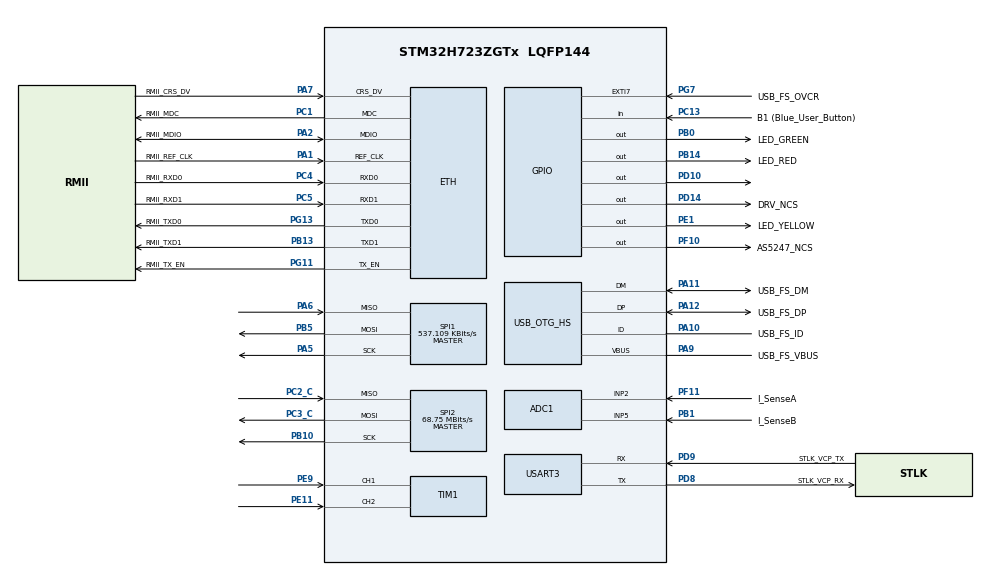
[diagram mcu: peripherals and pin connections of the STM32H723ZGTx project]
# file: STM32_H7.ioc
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ADC1.Channel-3\#ChannelRegularConversion=ADC_CHANNEL_2
ADC1.NbrOfConversionFlag=1
ADC1.OffsetNumber-3\#ChannelRegularConversion=ADC_OFFSET_NONE
ADC1.OffsetSignedSaturation-3\#ChannelRegularConversion=DISABLE
ADC1.Rank-3\#ChannelRegularConversion=1
ADC1.SamplingTime-3\#ChannelRegularConversion=ADC_SAMPLETIME_1CYCLE_5
ADC1.master=1
ETH.MediaInterface=HAL_ETH_RMII_MODE
Mcu.Family=STM32H7
Mcu.Name=STM32H723ZGTx
Mcu.Package=LQFP144
NVIC.PriorityGroup=NVIC_PRIORITYGROUP_4
PA1.GPIO_Label=RMII_REF_CLK
PA1.Mode=RMII
PA1.Signal=ETH_REF_CLK
PA10.GPIO_Label=USB_FS_ID
PA10.Mode=OTG/Dual-Role-Device-FS
PA10.Signal=USB_OTG_HS_ID
PA11.GPIO_Label=USB_FS_DM
PA11.Mode=OTG/Dual-Role-Device-FS
PA11.Signal=USB_OTG_HS_DM
PA12.GPIO_Label=USB_FS_DP
PA12.Mode=OTG/Dual-Role-Device-FS
PA12.Signal=USB_OTG_HS_DP
PA13(JTMS/SWDIO).GPIO_Label=SWDIO
PA13(JTMS/SWDIO).Mode=Trace_Asynchronous_SW
PA13(JTMS/SWDIO).Signal=DEBUG_JTMS-SWDIO
PA14(JTCK/SWCLK).GPIO_Label=SWCLK
PA14(JTCK/SWCLK).Mode=Trace_Asynchronous_SW
PA14(JTCK/SWCLK).Signal=DEBUG_JTCK-SWCLK
PA2.GPIO_Label=RMII_MDIO
PA2.Mode=RMII
PA2.Signal=ETH_MDIO
PA5.Mode=Full_Duplex_Master
PA5.Signal=SPI1_SCK
PA6.Mode=Full_Duplex_Master
PA6.Signal=SPI1_MISO
PA7.GPIO_Label=RMII_CRS_DV
PA7.Mode=RMII
PA7.Signal=ETH_CRS_DV
PA9.GPIO_Label=USB_FS_VBUS
PA9.Mode=Activate_VBUS_FS
PA9.Signal=USB_OTG_HS_VBUS
PB0.GPIO_Label=LED_GREEN
PB0.Signal=GPIO_Output
PB1.GPIO_Label=I_SenseB
PB1.Signal=ADCx_INP5
PB10.Mode=Full_Duplex_Master
PB10.Signal=SPI2_SCK
PB13.GPIO_Label=RMII_TXD1
PB13.Mode=RMII
PB13.Signal=ETH_TXD1
PB14.GPIO_Label=LED_RED
PB14.Signal=GPIO_Output
PB3(JTDO/TRACESWO).GPIO_Label=SWO
PB3(JTDO/TRACESWO).Mode=Trace_Asynchronous_SW
PB3(JTDO/TRACESWO).Signal=DEBUG_JTDO-SWO
PB5.Mode=Full_Duplex_Master
PB5.Signal=SPI1_MOSI
PC1.GPIO_Label=RMII_MDC
PC1.Mode=RMII
PC1.Signal=ETH_MDC
PC13.GPIO_Label=B1 (Blue_User_Button)
PC13.Signal=GPIO_Input
PC14-OSC32_IN.Mode=LSE-External-Oscillator
PC14-OSC32_IN.Signal=RCC_OSC32_IN
PC15-OSC32_OUT.Mode=LSE-External-Oscillator
PC15-OSC32_OUT.Signal=RCC_OSC32_OUT
PC2_C.Mode=Full_Duplex_Master
PC2_C.Signal=SPI2_MISO
PC3_C.Mode=Full_Duplex_Master
PC3_C.Signal=SPI2_MOSI
PC4.GPIO_Label=RMII_RXD0
PC4.Mode=RMII
PC4.Signal=ETH_RXD0
PC5.GPIO_Label=RMII_RXD1
PC5.Mode=RMII
PC5.Signal=ETH_RXD1
PD10.Signal=GPIO_Output
PD14.GPIO_Label=DRV_NCS
PD14.Signal=GPIO_Output
PD8.GPIO_Label=STLK_VCP_RX
PD8.Mode=Asynchronous
PD8.Signal=USART3_TX
PD9.GPIO_Label=STLK_VCP_TX
PD9.Mode=Asynchronous
PD9.Signal=USART3_RX
PE1.GPIO_Label=LED_YELLOW
PE1.Signal=GPIO_Output
PE11.Signal=S_TIM1_CH2
PE9.Signal=S_TIM1_CH1
PF10.GPIO_Label=AS5247_NCS
PF10.Signal=GPIO_Output
PF11.GPIO_Label=I_SenseA
PF11.Mode=IN2-Single-Ended
PF11.Signal=ADC1_INP2
PG11.GPIO_Label=RMII_TX_EN
PG11.Mode=RMII
PG11.Signal=ETH_TX_EN
PG13.GPIO_Label=RMII_TXD0
PG13.Mode=RMII
PG13.Signal=ETH_TXD0
PG7.GPIO_Label=USB_FS_OVCR
PG7.Signal=GPXTI7
PH0-OSC_IN.GPIO_Label=MCO
PH0-OSC_IN.Mode=HSE-External-Clock-Source
PH0-OSC_IN.Signal=RCC_OSC_IN
PH1-OSC_OUT.Signal=RCC_OSC_OUT
ProjectManager.HeapSize=0x200
ProjectManager.StackSize=0x400
ProjectManager.TargetToolchain=STM32CubeIDE
RCC.ADCFreq_Value=96000000
RCC.APB1Freq_Value=137500000
RCC.APB2Freq_Value=137500000
RCC.APB3Freq_Value=137500000
RCC.APB4Freq_Value=137500000
RCC.CortexFreq_Value=550000000
RCC.D1PPRE=RCC_APB3_DIV2
RCC.D2PPRE1=RCC_APB1_DIV2
RCC.D2PPRE2=RCC_APB2_DIV2
RCC.D3PPRE=RCC_APB4_DIV2
RCC.DIVM1=4
RCC.DIVM2=1
RCC.DIVN1=275
RCC.DIVN2=24
RCC.DIVP1=1
RCC.DIVQ1=4
RCC.HCLKFreq_Value=275000000
RCC.HPRE=RCC_HCLK_DIV2
RCC.HSE_VALUE=8000000
RCC.PLLFRACN=0
RCC.PLLSourceVirtual=RCC_PLLSOURCE_HSE
RCC.SYSCLKFreq_VALUE=550000000
RCC.SYSCLKSource=RCC_SYSCLKSOURCE_PLLCLK
RCC.USBCLockSelection=RCC_USBCLKSOURCE_HSI48
RCC.USBFreq_Value=48000000
SH.ADCx_INP5.0=ADC1_INP5,IN5-Single-Ended
SH.S_TIM1_CH1.0=TIM1_CH1,Encoder_Interface
SH.S_TIM1_CH2.0=TIM1_CH2,Encoder_Interface
SPI1.BaudRatePrescaler=SPI_BAUDRATEPRESCALER_256
SPI1.CLKPhase=SPI_PHASE_2EDGE
SPI1.CalculateBaudRate=537.109 KBits/s
SPI1.DataSize=SPI_DATASIZE_16BIT
SPI1.Direction=SPI_DIRECTION_2LINES
SPI1.Mode=SPI_MODE_MASTER
SPI1.NSSPMode=SPI_NSS_PULSE_ENABLE
SPI1.VirtualType=VM_MASTER
SPI2.CalculateBaudRate=68.75 MBits/s
SPI2.Direction=SPI_DIRECTION_2LINES
SPI2.Mode=SPI_MODE_MASTER
SPI2.VirtualType=VM_MASTER
USART3.VirtualMode-Asynchronous=VM_ASYNC
board=NUCLEO-H723ZG

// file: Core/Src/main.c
/* USER CODE BEGIN Header */
/**
  ******************************************************************************
  * @file           : main.c
  * @brief          : Main program body
  ******************************************************************************
  * @attention
  *
  * <h2><center>&copy; Copyright (c) 2021 STMicroelectronics.
  * All rights reserved.</center></h2>
  *
  * This software component is licensed by ST under BSD 3-Clause license,
  * the "License"; You may not use this file except in compliance with the
  * License. You may obtain a copy of the License at:
  *                        opensource.org/licenses/BSD-3-Clause
  *
  ******************************************************************************
  */
/* USER CODE END Header */
#include "main.h"
#include "string.h"

/* USER CODE BEGIN Includes */
#include "as5247u.h"
/* USER CODE END Includes */

#if defined ( __ICCARM__ ) /*!< IAR Compiler */

#pragma location=0x30040000
ETH_DMADescTypeDef  DMARxDscrTab[ETH_RX_DESC_CNT]; /* Ethernet Rx DMA Descriptors */
#pragma location=0x30040060
ETH_DMADescTypeDef  DMATxDscrTab[ETH_TX_DESC_CNT]; /* Ethernet Tx DMA Descriptors */
#pragma location=0x30040200
uint8_t Rx_Buff[ETH_RX_DESC_CNT][ETH_MAX_PACKET_SIZE]; /* Ethernet Receive Buffers */

#elif defined ( __CC_ARM )  /* MDK ARM Compiler */

__attribute__((at(0x30040000))) ETH_DMADescTypeDef  DMARxDscrTab[ETH_RX_DESC_CNT]; /* Ethernet Rx DMA Descriptors */
__attribute__((at(0x30040060))) ETH_DMADescTypeDef  DMATxDscrTab[ETH_TX_DESC_CNT]; /* Ethernet Tx DMA Descriptors */
__attribute__((at(0x30040200))) uint8_t Rx_Buff[ETH_RX_DESC_CNT][ETH_MAX_PACKET_SIZE]; /* Ethernet Receive Buffer */

#elif defined ( __GNUC__ ) /* GNU Compiler */

ETH_DMADescTypeDef DMARxDscrTab[ETH_RX_DESC_CNT] __attribute__((section(".RxDecripSection"))); /* Ethernet Rx DMA Descriptors */
ETH_DMADescTypeDef DMATxDscrTab[ETH_TX_DESC_CNT] __attribute__((section(".TxDecripSection")));   /* Ethernet Tx DMA Descriptors */
uint8_t Rx_Buff[ETH_RX_DESC_CNT][ETH_MAX_PACKET_SIZE] __attribute__((section(".RxArraySection"))); /* Ethernet Receive Buffers */

#endif

ETH_TxPacketConfig TxConfig;
ADC_HandleTypeDef hadc1;

ETH_HandleTypeDef heth;

SPI_HandleTypeDef hspi1;
SPI_HandleTypeDef hspi2;

TIM_HandleTypeDef htim1;

UART_HandleTypeDef huart3;

void SystemClock_Config(void);
static void MX_GPIO_Init(void);
static void MX_ETH_Init(void);
static void MX_USART3_UART_Init(void);
static void MX_USB_OTG_HS_USB_Init(void);
static void MX_SPI1_Init(void);
static void MX_ADC1_Init(void);
static void MX_TIM1_Init(void);
static void MX_SPI2_Init(void);

int main(void)
{

  /* MCU Configuration--------------------------------------------------------*/

  /* Reset of all peripherals, Initializes the Flash interface and the Systick. */
  HAL_Init();

  /* Configure the system clock */
  SystemClock_Config();

  /* Initialize all configured peripherals */
  MX_GPIO_Init();
  MX_ETH_Init();
  MX_USART3_UART_Init();
  MX_USB_OTG_HS_USB_Init();
  MX_SPI1_Init();
  MX_ADC1_Init();
  MX_TIM1_Init();
  MX_SPI2_Init();
  /* USER CODE BEGIN 2 */
  AS5247U enc;
  AS5247U_Initialize(&enc, &hspi1, NULL,AS5247_NCS_GPIO_Port, 0, AS5247_NCS_Pin);
  /* USER CODE END 2 */

  /* Infinite loop */
  /* USER CODE BEGIN WHILE */
  while (1)
  {
//      HAL_GPIO_WritePin(AS5247_NCS_GPIO_Port, AS5247_NCS_Pin, GPIO_PIN_SET);
//      HAL_Delay(100);
	  uint16_t data = AS5247U_GetErrorReg(&enc);
      HAL_Delay(100);

    /* USER CODE END WHILE */

  }
}

void SystemClock_Config(void)
{
  RCC_OscInitTypeDef RCC_OscInitStruct = {0};
  RCC_ClkInitTypeDef RCC_ClkInitStruct = {0};

  /** Supply configuration update enable
  */
  HAL_PWREx_ConfigSupply(PWR_LDO_SUPPLY);
  /** Configure the main internal regulator output voltage
  */
  __HAL_PWR_VOLTAGESCALING_CONFIG(PWR_REGULATOR_VOLTAGE_SCALE0);

  while(!__HAL_PWR_GET_FLAG(PWR_FLAG_VOSRDY)) {}
  /** Macro to configure the PLL clock source
  */
  __HAL_RCC_PLL_PLLSOURCE_CONFIG(RCC_PLLSOURCE_HSE);
  /** Initializes the RCC Oscillators according to the specified parameters
  * in the RCC_OscInitTypeDef structure.
  */
  RCC_OscInitStruct.OscillatorType = RCC_OSCILLATORTYPE_HSI48|RCC_OSCILLATORTYPE_HSE;
  RCC_OscInitStruct.HSEState = RCC_HSE_BYPASS;
  RCC_OscInitStruct.HSI48State = RCC_HSI48_ON;
  RCC_OscInitStruct.PLL.PLLState = RCC_PLL_ON;
  RCC_OscInitStruct.PLL.PLLSource = RCC_PLLSOURCE_HSE;
  RCC_OscInitStruct.PLL.PLLM = 4;
  RCC_OscInitStruct.PLL.PLLN = 275;
  RCC_OscInitStruct.PLL.PLLP = 1;
  RCC_OscInitStruct.PLL.PLLQ = 4;
  RCC_OscInitStruct.PLL.PLLR = 2;
  RCC_OscInitStruct.PLL.PLLRGE = RCC_PLL1VCIRANGE_1;
  RCC_OscInitStruct.PLL.PLLVCOSEL = RCC_PLL1VCOWIDE;
  RCC_OscInitStruct.PLL.PLLFRACN = 0;
  if (HAL_RCC_OscConfig(&RCC_OscInitStruct) != HAL_OK)
  {
    Error_Handler();
  }
  /** Initializes the CPU, AHB and APB buses clocks
  */
  RCC_ClkInitStruct.ClockType = RCC_CLOCKTYPE_HCLK|RCC_CLOCKTYPE_SYSCLK
                              |RCC_CLOCKTYPE_PCLK1|RCC_CLOCKTYPE_PCLK2
                              |RCC_CLOCKTYPE_D3PCLK1|RCC_CLOCKTYPE_D1PCLK1;
  RCC_ClkInitStruct.SYSCLKSource = RCC_SYSCLKSOURCE_PLLCLK;
  RCC_ClkInitStruct.SYSCLKDivider = RCC_SYSCLK_DIV1;
  RCC_ClkInitStruct.AHBCLKDivider = RCC_HCLK_DIV2;
  RCC_ClkInitStruct.APB3CLKDivider = RCC_APB3_DIV2;
  RCC_ClkInitStruct.APB1CLKDivider = RCC_APB1_DIV2;
  RCC_ClkInitStruct.APB2CLKDivider = RCC_APB2_DIV2;
  RCC_ClkInitStruct.APB4CLKDivider = RCC_APB4_DIV2;

  if (HAL_RCC_ClockConfig(&RCC_ClkInitStruct, FLASH_LATENCY_3) != HAL_OK)
  {
    Error_Handler();
  }
}

static void MX_ADC1_Init(void)
{

  ADC_MultiModeTypeDef multimode = {0};
  ADC_ChannelConfTypeDef sConfig = {0};

  /** Common config
  */
  hadc1.Instance = ADC1;
  hadc1.Init.ClockPrescaler = ADC_CLOCK_ASYNC_DIV1;
  hadc1.Init.Resolution = ADC_RESOLUTION_16B;
  hadc1.Init.ScanConvMode = ADC_SCAN_DISABLE;
  hadc1.Init.EOCSelection = ADC_EOC_SINGLE_CONV;
  hadc1.Init.LowPowerAutoWait = DISABLE;
  hadc1.Init.ContinuousConvMode = DISABLE;
  hadc1.Init.NbrOfConversion = 1;
  hadc1.Init.DiscontinuousConvMode = DISABLE;
  hadc1.Init.ExternalTrigConv = ADC_SOFTWARE_START;
  hadc1.Init.ExternalTrigConvEdge = ADC_EXTERNALTRIGCONVEDGE_NONE;
  hadc1.Init.ConversionDataManagement = ADC_CONVERSIONDATA_DR;
  hadc1.Init.Overrun = ADC_OVR_DATA_PRESERVED;
  hadc1.Init.LeftBitShift = ADC_LEFTBITSHIFT_NONE;
  hadc1.Init.OversamplingMode = DISABLE;
  if (HAL_ADC_Init(&hadc1) != HAL_OK)
  {
    Error_Handler();
  }
  /** Configure the ADC multi-mode
  */
  multimode.Mode = ADC_MODE_INDEPENDENT;
  if (HAL_ADCEx_MultiModeConfigChannel(&hadc1, &multimode) != HAL_OK)
  {
    Error_Handler();
  }
  /** Configure Regular Channel
  */
  sConfig.Channel = ADC_CHANNEL_2;
  sConfig.Rank = ADC_REGULAR_RANK_1;
  sConfig.SamplingTime = ADC_SAMPLETIME_1CYCLE_5;
  sConfig.SingleDiff = ADC_SINGLE_ENDED;
  sConfig.OffsetNumber = ADC_OFFSET_NONE;
  sConfig.Offset = 0;
  sConfig.OffsetSignedSaturation = DISABLE;
  if (HAL_ADC_ConfigChannel(&hadc1, &sConfig) != HAL_OK)
  {
    Error_Handler();
  }

}

static void MX_ETH_Init(void)
{

   static uint8_t MACAddr[6];

  heth.Instance = ETH;
  MACAddr[0] = 0x00;
  MACAddr[1] = 0x80;
  MACAddr[2] = 0xE1;
  MACAddr[3] = 0x00;
  MACAddr[4] = 0x00;
  MACAddr[5] = 0x00;
  heth.Init.MACAddr = &MACAddr[0];
  heth.Init.MediaInterface = HAL_ETH_RMII_MODE;
  heth.Init.TxDesc = DMATxDscrTab;
  heth.Init.RxDesc = DMARxDscrTab;
  heth.Init.RxBuffLen = 1524;

  if (HAL_ETH_Init(&heth) != HAL_OK)
  {
    Error_Handler();
  }

  memset(&TxConfig, 0 , sizeof(ETH_TxPacketConfig));
  TxConfig.Attributes = ETH_TX_PACKETS_FEATURES_CSUM | ETH_TX_PACKETS_FEATURES_CRCPAD;
  TxConfig.ChecksumCtrl = ETH_CHECKSUM_IPHDR_PAYLOAD_INSERT_PHDR_CALC;
  TxConfig.CRCPadCtrl = ETH_CRC_PAD_INSERT;

}

static void MX_SPI1_Init(void)
{

  /* SPI1 parameter configuration*/
  hspi1.Instance = SPI1;
  hspi1.Init.Mode = SPI_MODE_MASTER;
  hspi1.Init.Direction = SPI_DIRECTION_2LINES;
  hspi1.Init.DataSize = SPI_DATASIZE_16BIT;
  hspi1.Init.CLKPolarity = SPI_POLARITY_LOW;
  hspi1.Init.CLKPhase = SPI_PHASE_2EDGE;
  hspi1.Init.NSS = SPI_NSS_SOFT;
  hspi1.Init.BaudRatePrescaler = SPI_BAUDRATEPRESCALER_256;
  hspi1.Init.FirstBit = SPI_FIRSTBIT_MSB;
  hspi1.Init.TIMode = SPI_TIMODE_DISABLE;
  hspi1.Init.CRCCalculation = SPI_CRCCALCULATION_DISABLE;
  hspi1.Init.CRCPolynomial = 0x0;
  hspi1.Init.NSSPMode = SPI_NSS_PULSE_ENABLE;
  hspi1.Init.NSSPolarity = SPI_NSS_POLARITY_LOW;
  hspi1.Init.FifoThreshold = SPI_FIFO_THRESHOLD_01DATA;
  hspi1.Init.TxCRCInitializationPattern = SPI_CRC_INITIALIZATION_ALL_ZERO_PATTERN;
  hspi1.Init.RxCRCInitializationPattern = SPI_CRC_INITIALIZATION_ALL_ZERO_PATTERN;
  hspi1.Init.MasterSSIdleness = SPI_MASTER_SS_IDLENESS_00CYCLE;
  hspi1.Init.MasterInterDataIdleness = SPI_MASTER_INTERDATA_IDLENESS_00CYCLE;
  hspi1.Init.MasterReceiverAutoSusp = SPI_MASTER_RX_AUTOSUSP_DISABLE;
  hspi1.Init.MasterKeepIOState = SPI_MASTER_KEEP_IO_STATE_DISABLE;
  hspi1.Init.IOSwap = SPI_IO_SWAP_DISABLE;
  if (HAL_SPI_Init(&hspi1) != HAL_OK)
  {
    Error_Handler();
  }

}

static void MX_SPI2_Init(void)
{

  /* SPI2 parameter configuration*/
  hspi2.Instance = SPI2;
  hspi2.Init.Mode = SPI_MODE_MASTER;
  hspi2.Init.Direction = SPI_DIRECTION_2LINES;
  hspi2.Init.DataSize = SPI_DATASIZE_4BIT;
  hspi2.Init.CLKPolarity = SPI_POLARITY_LOW;
  hspi2.Init.CLKPhase = SPI_PHASE_1EDGE;
  hspi2.Init.NSS = SPI_NSS_SOFT;
  hspi2.Init.BaudRatePrescaler = SPI_BAUDRATEPRESCALER_2;
  hspi2.Init.FirstBit = SPI_FIRSTBIT_MSB;
  hspi2.Init.TIMode = SPI_TIMODE_DISABLE;
  hspi2.Init.CRCCalculation = SPI_CRCCALCULATION_DISABLE;
  hspi2.Init.CRCPolynomial = 0x0;
  hspi2.Init.NSSPMode = SPI_NSS_PULSE_ENABLE;
  hspi2.Init.NSSPolarity = SPI_NSS_POLARITY_LOW;
  hspi2.Init.FifoThreshold = SPI_FIFO_THRESHOLD_01DATA;
  hspi2.Init.TxCRCInitializationPattern = SPI_CRC_INITIALIZATION_ALL_ZERO_PATTERN;
  hspi2.Init.RxCRCInitializationPattern = SPI_CRC_INITIALIZATION_ALL_ZERO_PATTERN;
  hspi2.Init.MasterSSIdleness = SPI_MASTER_SS_IDLENESS_00CYCLE;
  hspi2.Init.MasterInterDataIdleness = SPI_MASTER_INTERDATA_IDLENESS_00CYCLE;
  hspi2.Init.MasterReceiverAutoSusp = SPI_MASTER_RX_AUTOSUSP_DISABLE;
  hspi2.Init.MasterKeepIOState = SPI_MASTER_KEEP_IO_STATE_DISABLE;
  hspi2.Init.IOSwap = SPI_IO_SWAP_DISABLE;
  if (HAL_SPI_Init(&hspi2) != HAL_OK)
  {
    Error_Handler();
  }

}

static void MX_TIM1_Init(void)
{

  TIM_Encoder_InitTypeDef sConfig = {0};
  TIM_MasterConfigTypeDef sMasterConfig = {0};

  htim1.Instance = TIM1;
  htim1.Init.Prescaler = 0;
  htim1.Init.CounterMode = TIM_COUNTERMODE_UP;
  htim1.Init.Period = 65535;
  htim1.Init.ClockDivision = TIM_CLOCKDIVISION_DIV1;
  htim1.Init.RepetitionCounter = 0;
  htim1.Init.AutoReloadPreload = TIM_AUTORELOAD_PRELOAD_DISABLE;
  sConfig.EncoderMode = TIM_ENCODERMODE_TI1;
  sConfig.IC1Polarity = TIM_ICPOLARITY_RISING;
  sConfig.IC1Selection = TIM_ICSELECTION_DIRECTTI;
  sConfig.IC1Prescaler = TIM_ICPSC_DIV1;
  sConfig.IC1Filter = 0;
  sConfig.IC2Polarity = TIM_ICPOLARITY_RISING;
  sConfig.IC2Selection = TIM_ICSELECTION_DIRECTTI;
  sConfig.IC2Prescaler = TIM_ICPSC_DIV1;
  sConfig.IC2Filter = 0;
  if (HAL_TIM_Encoder_Init(&htim1, &sConfig) != HAL_OK)
  {
    Error_Handler();
  }
  sMasterConfig.MasterOutputTrigger = TIM_TRGO_RESET;
  sMasterConfig.MasterOutputTrigger2 = TIM_TRGO2_RESET;
  sMasterConfig.MasterSlaveMode = TIM_MASTERSLAVEMODE_DISABLE;
  if (HAL_TIMEx_MasterConfigSynchronization(&htim1, &sMasterConfig) != HAL_OK)
  {
    Error_Handler();
  }

}

static void MX_USART3_UART_Init(void)
{

  huart3.Instance = USART3;
  huart3.Init.BaudRate = 115200;
  huart3.Init.WordLength = UART_WORDLENGTH_8B;
  huart3.Init.StopBits = UART_STOPBITS_1;
  huart3.Init.Parity = UART_PARITY_NONE;
  huart3.Init.Mode = UART_MODE_TX_RX;
  huart3.Init.HwFlowCtl = UART_HWCONTROL_NONE;
  huart3.Init.OverSampling = UART_OVERSAMPLING_16;
  huart3.Init.OneBitSampling = UART_ONE_BIT_SAMPLE_DISABLE;
  huart3.Init.ClockPrescaler = UART_PRESCALER_DIV1;
  huart3.AdvancedInit.AdvFeatureInit = UART_ADVFEATURE_NO_INIT;
  if (HAL_UART_Init(&huart3) != HAL_OK)
  {
    Error_Handler();
  }
  if (HAL_UARTEx_SetTxFifoThreshold(&huart3, UART_TXFIFO_THRESHOLD_1_8) != HAL_OK)
  {
    Error_Handler();
  }
  if (HAL_UARTEx_SetRxFifoThreshold(&huart3, UART_RXFIFO_THRESHOLD_1_8) != HAL_OK)
  {
    Error_Handler();
  }
  if (HAL_UARTEx_DisableFifoMode(&huart3) != HAL_OK)
  {
    Error_Handler();
  }

}

static void MX_USB_OTG_HS_USB_Init(void)
{

}

static void MX_GPIO_Init(void)
{
  GPIO_InitTypeDef GPIO_InitStruct = {0};

  /* GPIO Ports Clock Enable */
  __HAL_RCC_GPIOC_CLK_ENABLE();
  __HAL_RCC_GPIOF_CLK_ENABLE();
  __HAL_RCC_GPIOH_CLK_ENABLE();
  __HAL_RCC_GPIOA_CLK_ENABLE();
  __HAL_RCC_GPIOB_CLK_ENABLE();
  __HAL_RCC_GPIOE_CLK_ENABLE();
  __HAL_RCC_GPIOD_CLK_ENABLE();
  __HAL_RCC_GPIOG_CLK_ENABLE();

  /*Configure GPIO pin Output Level */
  HAL_GPIO_WritePin(AS5247_NCS_GPIO_Port, AS5247_NCS_Pin, GPIO_PIN_RESET);

  /*Configure GPIO pin Output Level */
  HAL_GPIO_WritePin(GPIOB, LED_GREEN_Pin|LED_RED_Pin, GPIO_PIN_RESET);

  /*Configure GPIO pin Output Level */
  HAL_GPIO_WritePin(GPIOD, GPIO_PIN_10|DRV_NCS_Pin, GPIO_PIN_RESET);

  /*Configure GPIO pin Output Level */
  HAL_GPIO_WritePin(LED_YELLOW_GPIO_Port, LED_YELLOW_Pin, GPIO_PIN_RESET);

  /*Configure GPIO pin : B1_Pin */
  GPIO_InitStruct.Pin = B1_Pin;
  GPIO_InitStruct.Mode = GPIO_MODE_INPUT;
  GPIO_InitStruct.Pull = GPIO_NOPULL;
  HAL_GPIO_Init(B1_GPIO_Port, &GPIO_InitStruct);

  /*Configure GPIO pin : AS5247_NCS_Pin */
  GPIO_InitStruct.Pin = AS5247_NCS_Pin;
  GPIO_InitStruct.Mode = GPIO_MODE_OUTPUT_PP;
  GPIO_InitStruct.Pull = GPIO_NOPULL;
  GPIO_InitStruct.Speed = GPIO_SPEED_FREQ_LOW;
  HAL_GPIO_Init(AS5247_NCS_GPIO_Port, &GPIO_InitStruct);

  /*Configure GPIO pins : LED_GREEN_Pin LED_RED_Pin */
  GPIO_InitStruct.Pin = LED_GREEN_Pin|LED_RED_Pin;
  GPIO_InitStruct.Mode = GPIO_MODE_OUTPUT_PP;
  GPIO_InitStruct.Pull = GPIO_NOPULL;
  GPIO_InitStruct.Speed = GPIO_SPEED_FREQ_LOW;
  HAL_GPIO_Init(GPIOB, &GPIO_InitStruct);

  /*Configure GPIO pins : PD10 DRV_NCS_Pin */
  GPIO_InitStruct.Pin = GPIO_PIN_10|DRV_NCS_Pin;
  GPIO_InitStruct.Mode = GPIO_MODE_OUTPUT_PP;
  GPIO_InitStruct.Pull = GPIO_NOPULL;
  GPIO_InitStruct.Speed = GPIO_SPEED_FREQ_LOW;
  HAL_GPIO_Init(GPIOD, &GPIO_InitStruct);

  /*Configure GPIO pin : USB_FS_OVCR_Pin */
  GPIO_InitStruct.Pin = USB_FS_OVCR_Pin;
  GPIO_InitStruct.Mode = GPIO_MODE_IT_RISING;
  GPIO_InitStruct.Pull = GPIO_NOPULL;
  HAL_GPIO_Init(USB_FS_OVCR_GPIO_Port, &GPIO_InitStruct);

  /*Configure GPIO pin : USB_FS_VBUS_Pin */
  GPIO_InitStruct.Pin = USB_FS_VBUS_Pin;
  GPIO_InitStruct.Mode = GPIO_MODE_INPUT;
  GPIO_InitStruct.Pull = GPIO_NOPULL;
  HAL_GPIO_Init(USB_FS_VBUS_GPIO_Port, &GPIO_InitStruct);

  /*Configure GPIO pin : USB_FS_ID_Pin */
  GPIO_InitStruct.Pin = USB_FS_ID_Pin;
  GPIO_InitStruct.Mode = GPIO_MODE_AF_PP;
  GPIO_InitStruct.Pull = GPIO_NOPULL;
  GPIO_InitStruct.Speed = GPIO_SPEED_FREQ_LOW;
  GPIO_InitStruct.Alternate = GPIO_AF10_OTG1_HS;
  HAL_GPIO_Init(USB_FS_ID_GPIO_Port, &GPIO_InitStruct);

  /*Configure GPIO pin : LED_YELLOW_Pin */
  GPIO_InitStruct.Pin = LED_YELLOW_Pin;
  GPIO_InitStruct.Mode = GPIO_MODE_OUTPUT_PP;
  GPIO_InitStruct.Pull = GPIO_NOPULL;
  GPIO_InitStruct.Speed = GPIO_SPEED_FREQ_LOW;
  HAL_GPIO_Init(LED_YELLOW_GPIO_Port, &GPIO_InitStruct);

}

void Error_Handler(void)
{
  __disable_irq();
  while (1)
  {
  }
}

/************************ (C) COPYRIGHT STMicroelectronics *****END OF FILE****/
